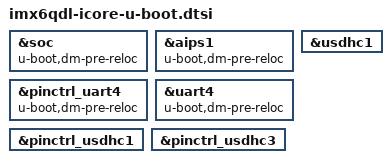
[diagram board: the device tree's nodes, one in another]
// SPDX-License-Identifier: GPL-2.0+
/*
 * Copyright (C) 2018 Jagan Teki <jagan@amarulasolutions.com>
 */

#include "imx6qdl-u-boot.dtsi"

&soc {
	u-boot,dm-pre-reloc;
};

&aips1 {
	u-boot,dm-pre-reloc;
};

&pinctrl_uart4 {
	u-boot,dm-pre-reloc;
};

&uart4 {
	u-boot,dm-pre-reloc;
};

&usdhc1 {
	u-boot,dm-spl;
};

&pinctrl_usdhc1 {
	u-boot,dm-spl;
};

&pinctrl_usdhc3 {
	u-boot,dm-spl;
};
